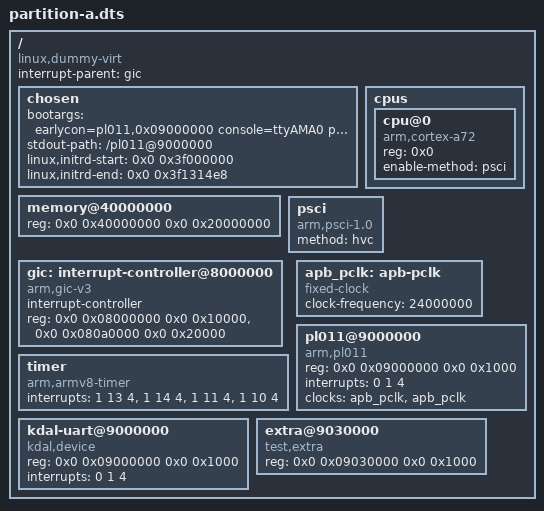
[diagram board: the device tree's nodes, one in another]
// Device tree for a Linux guest in HAVEN partition A on QEMU virt.
// IPA layout from src/core/partition.c and the qemu-virt grant:
// RAM 512 MiB at IPA 0x40000000 (PA 0x80800000), PL011 at 0x09000000 with
// SPI 1 (INTID 33). The GIC and PSCI entries describe what Linux expects;
// HAVEN does not yet emulate them (steps L1 to L3 of PLAN.md).
/dts-v1/;

/ {
	compatible = "linux,dummy-virt";
	#address-cells = <2>;
	#size-cells = <2>;
	interrupt-parent = <&gic>;

	chosen {
		bootargs = "earlycon=pl011,0x09000000 console=ttyAMA0 panic=-1 rdinit=/init";
		stdout-path = "/pl011@9000000";
		linux,initrd-start = <0x0 0x3f000000>;
		linux,initrd-end = <0x0 0x3f1314e8>;
	};

	memory@40000000 {
		device_type = "memory";
		reg = <0x0 0x40000000 0x0 0x20000000>;
	};

	cpus {
		#address-cells = <1>;
		#size-cells = <0>;
		cpu@0 {
			device_type = "cpu";
			compatible = "arm,cortex-a72";
			reg = <0x0>;
			enable-method = "psci";
		};
	};

	psci {
		compatible = "arm,psci-1.0", "arm,psci-0.2";
		method = "hvc";
	};

	gic: interrupt-controller@8000000 {
		compatible = "arm,gic-v3";
		#interrupt-cells = <3>;
		interrupt-controller;
		reg = <0x0 0x08000000 0x0 0x10000>,	/* GICD */
		      <0x0 0x080a0000 0x0 0x20000>;	/* GICR, one CPU */
	};

	timer {
		compatible = "arm,armv8-timer";
		interrupts = <1 13 4>, <1 14 4>, <1 11 4>, <1 10 4>;
	};

	apb_pclk: apb-pclk {
		compatible = "fixed-clock";
		#clock-cells = <0>;
		clock-frequency = <24000000>;
	};

	pl011@9000000 {
		compatible = "arm,pl011", "arm,primecell";
		reg = <0x0 0x09000000 0x0 0x1000>;
		interrupts = <0 1 4>;
		clocks = <&apb_pclk>, <&apb_pclk>;
		clock-names = "uartclk", "apb_pclk";
	};

	kdal-uart@9000000 {
		compatible = "kdal,device";
		reg = <0x0 0x09000000 0x0 0x1000>;
		interrupts = <0 1 4>;
	};

	extra@9030000 {
		compatible = "test,extra";
		reg = <0x0 0x09030000 0x0 0x1000>;
	};
};
